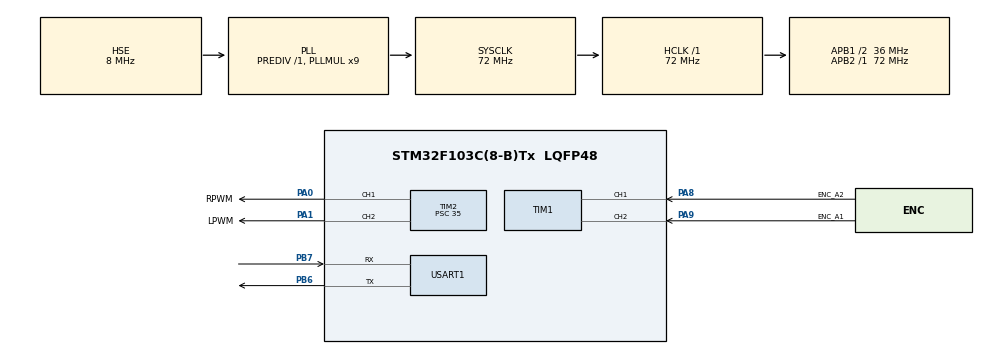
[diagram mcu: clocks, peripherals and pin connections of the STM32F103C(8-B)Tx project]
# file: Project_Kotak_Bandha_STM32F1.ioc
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Mcu.Family=STM32F1
Mcu.Name=STM32F103C(8-B)Tx
Mcu.Package=LQFP48
NVIC.PriorityGroup=NVIC_PRIORITYGROUP_4
PA0-WKUP.GPIO_Label=RPWM
PA0-WKUP.Signal=S_TIM2_CH1_ETR
PA1.GPIO_Label=LPWM
PA1.Signal=S_TIM2_CH2
PA13.Mode=Serial_Wire
PA13.Signal=SYS_JTMS-SWDIO
PA14.Mode=Serial_Wire
PA14.Signal=SYS_JTCK-SWCLK
PA8.GPIO_Label=ENC_A2
PA8.Signal=S_TIM1_CH1
PA9.GPIO_Label=ENC_A1
PA9.Signal=S_TIM1_CH2
PB6.Mode=Asynchronous
PB6.Signal=USART1_TX
PB7.Mode=Asynchronous
PB7.Signal=USART1_RX
PD0-OSC_IN.Mode=HSE-External-Oscillator
PD0-OSC_IN.Signal=RCC_OSC_IN
PD1-OSC_OUT.Mode=HSE-External-Oscillator
PD1-OSC_OUT.Signal=RCC_OSC_OUT
ProjectManager.HeapSize=0x200
ProjectManager.StackSize=0x400
ProjectManager.TargetToolchain=STM32CubeIDE
RCC.AHBFreq_Value=72000000
RCC.APB1CLKDivider=RCC_HCLK_DIV2
RCC.APB1Freq_Value=36000000
RCC.APB1TimFreq_Value=72000000
RCC.APB2Freq_Value=72000000
RCC.APB2TimFreq_Value=72000000
RCC.HCLKFreq_Value=72000000
RCC.PLLMUL=RCC_PLL_MUL9
RCC.PLLSourceVirtual=RCC_PLLSOURCE_HSE
RCC.SYSCLKFreq_VALUE=72000000
RCC.SYSCLKSource=RCC_SYSCLKSOURCE_PLLCLK
RCC.USBFreq_Value=72000000
SH.S_TIM1_CH1.0=TIM1_CH1,Encoder_Interface
SH.S_TIM1_CH2.0=TIM1_CH2,Encoder_Interface
SH.S_TIM2_CH1_ETR.0=TIM2_CH1,PWM Generation1 CH1
SH.S_TIM2_CH2.0=TIM2_CH2,PWM Generation2 CH2
TIM1.EncoderMode=TIM_ENCODERMODE_TI12
TIM2.Channel-PWM\ Generation1\ CH1=TIM_CHANNEL_1
TIM2.Channel-PWM\ Generation2\ CH2=TIM_CHANNEL_2
TIM2.Period=99
TIM2.Prescaler=35
USART1.VirtualMode=VM_ASYNC
board=custom

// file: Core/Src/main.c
/* USER CODE BEGIN Header */
/**
  ******************************************************************************
  * @file           : main.c
  * @brief          : Main program body
  ******************************************************************************
  * @attention
  *
  * Copyright (c) 2026 STMicroelectronics.
  * All rights reserved.
  *
  * This software is licensed under terms that can be found in the LICENSE file
  * in the root directory of this software component.
  * If no LICENSE file comes with this software, it is provided AS-IS.
  *
  ******************************************************************************
  */
/* USER CODE END Header */
#include "main.h"
#include "encoder.h"
#include "motor.h"
#include "pid_control.h"

TIM_HandleTypeDef htim1;
TIM_HandleTypeDef htim2;

UART_HandleTypeDef huart1;

/* USER CODE BEGIN PV */
int16_t encoder_value;
uint16_t duty_cycle = 0;
uint16_t ARR = 99;
/* USER CODE END PV */

void SystemClock_Config(void);
static void MX_GPIO_Init(void);
static void MX_TIM1_Init(void);
static void MX_TIM2_Init(void);
static void MX_USART1_UART_Init(void);

int main(void)
{

  /* MCU Configuration--------------------------------------------------------*/

  /* Reset of all peripherals, Initializes the Flash interface and the Systick. */
  HAL_Init();

  /* Configure the system clock */
  SystemClock_Config();

  /* Initialize all configured peripherals */
  MX_GPIO_Init();
  MX_TIM1_Init();
  MX_TIM2_Init();
  MX_USART1_UART_Init();
  /* USER CODE BEGIN 2 */
  Encoder_Init();
  Motor_Init();
  /* USER CODE END 2 */

  /* Infinite loop */
  /* USER CODE BEGIN WHILE */
  while (1)
  {
	  Encoder_Update();
	  int32_t position = Encoder_GetPosition();
	  HAL_Delay(1);

	  Motor_SetSignedPWM(10);
	  HAL_Delay(100);
	  Motor_Stop();
	  HAL_Delay(1000);
    /* USER CODE END WHILE */

  }
}

void SystemClock_Config(void)
{
  RCC_OscInitTypeDef RCC_OscInitStruct = {0};
  RCC_ClkInitTypeDef RCC_ClkInitStruct = {0};

  /** Initializes the RCC Oscillators according to the specified parameters
  * in the RCC_OscInitTypeDef structure.
  */
  RCC_OscInitStruct.OscillatorType = RCC_OSCILLATORTYPE_HSE;
  RCC_OscInitStruct.HSEState = RCC_HSE_ON;
  RCC_OscInitStruct.HSEPredivValue = RCC_HSE_PREDIV_DIV1;
  RCC_OscInitStruct.HSIState = RCC_HSI_ON;
  RCC_OscInitStruct.PLL.PLLState = RCC_PLL_ON;
  RCC_OscInitStruct.PLL.PLLSource = RCC_PLLSOURCE_HSE;
  RCC_OscInitStruct.PLL.PLLMUL = RCC_PLL_MUL9;
  if (HAL_RCC_OscConfig(&RCC_OscInitStruct) != HAL_OK)
  {
    Error_Handler();
  }

  /** Initializes the CPU, AHB and APB buses clocks
  */
  RCC_ClkInitStruct.ClockType = RCC_CLOCKTYPE_HCLK|RCC_CLOCKTYPE_SYSCLK
                              |RCC_CLOCKTYPE_PCLK1|RCC_CLOCKTYPE_PCLK2;
  RCC_ClkInitStruct.SYSCLKSource = RCC_SYSCLKSOURCE_PLLCLK;
  RCC_ClkInitStruct.AHBCLKDivider = RCC_SYSCLK_DIV1;
  RCC_ClkInitStruct.APB1CLKDivider = RCC_HCLK_DIV2;
  RCC_ClkInitStruct.APB2CLKDivider = RCC_HCLK_DIV1;

  if (HAL_RCC_ClockConfig(&RCC_ClkInitStruct, FLASH_LATENCY_2) != HAL_OK)
  {
    Error_Handler();
  }
}

static void MX_TIM1_Init(void)
{

  TIM_Encoder_InitTypeDef sConfig = {0};
  TIM_MasterConfigTypeDef sMasterConfig = {0};

  htim1.Instance = TIM1;
  htim1.Init.Prescaler = 0;
  htim1.Init.CounterMode = TIM_COUNTERMODE_UP;
  htim1.Init.Period = 65535;
  htim1.Init.ClockDivision = TIM_CLOCKDIVISION_DIV1;
  htim1.Init.RepetitionCounter = 0;
  htim1.Init.AutoReloadPreload = TIM_AUTORELOAD_PRELOAD_DISABLE;
  sConfig.EncoderMode = TIM_ENCODERMODE_TI12;
  sConfig.IC1Polarity = TIM_ICPOLARITY_RISING;
  sConfig.IC1Selection = TIM_ICSELECTION_DIRECTTI;
  sConfig.IC1Prescaler = TIM_ICPSC_DIV1;
  sConfig.IC1Filter = 0;
  sConfig.IC2Polarity = TIM_ICPOLARITY_RISING;
  sConfig.IC2Selection = TIM_ICSELECTION_DIRECTTI;
  sConfig.IC2Prescaler = TIM_ICPSC_DIV1;
  sConfig.IC2Filter = 0;
  if (HAL_TIM_Encoder_Init(&htim1, &sConfig) != HAL_OK)
  {
    Error_Handler();
  }
  sMasterConfig.MasterOutputTrigger = TIM_TRGO_RESET;
  sMasterConfig.MasterSlaveMode = TIM_MASTERSLAVEMODE_DISABLE;
  if (HAL_TIMEx_MasterConfigSynchronization(&htim1, &sMasterConfig) != HAL_OK)
  {
    Error_Handler();
  }

}

static void MX_TIM2_Init(void)
{

  TIM_MasterConfigTypeDef sMasterConfig = {0};
  TIM_OC_InitTypeDef sConfigOC = {0};

  htim2.Instance = TIM2;
  htim2.Init.Prescaler = 35;
  htim2.Init.CounterMode = TIM_COUNTERMODE_UP;
  htim2.Init.Period = 99;
  htim2.Init.ClockDivision = TIM_CLOCKDIVISION_DIV1;
  htim2.Init.AutoReloadPreload = TIM_AUTORELOAD_PRELOAD_DISABLE;
  if (HAL_TIM_PWM_Init(&htim2) != HAL_OK)
  {
    Error_Handler();
  }
  sMasterConfig.MasterOutputTrigger = TIM_TRGO_RESET;
  sMasterConfig.MasterSlaveMode = TIM_MASTERSLAVEMODE_DISABLE;
  if (HAL_TIMEx_MasterConfigSynchronization(&htim2, &sMasterConfig) != HAL_OK)
  {
    Error_Handler();
  }
  sConfigOC.OCMode = TIM_OCMODE_PWM1;
  sConfigOC.Pulse = 0;
  sConfigOC.OCPolarity = TIM_OCPOLARITY_HIGH;
  sConfigOC.OCFastMode = TIM_OCFAST_DISABLE;
  if (HAL_TIM_PWM_ConfigChannel(&htim2, &sConfigOC, TIM_CHANNEL_1) != HAL_OK)
  {
    Error_Handler();
  }
  if (HAL_TIM_PWM_ConfigChannel(&htim2, &sConfigOC, TIM_CHANNEL_2) != HAL_OK)
  {
    Error_Handler();
  }
  HAL_TIM_MspPostInit(&htim2);

}

static void MX_USART1_UART_Init(void)
{

  huart1.Instance = USART1;
  huart1.Init.BaudRate = 115200;
  huart1.Init.WordLength = UART_WORDLENGTH_8B;
  huart1.Init.StopBits = UART_STOPBITS_1;
  huart1.Init.Parity = UART_PARITY_NONE;
  huart1.Init.Mode = UART_MODE_TX_RX;
  huart1.Init.HwFlowCtl = UART_HWCONTROL_NONE;
  huart1.Init.OverSampling = UART_OVERSAMPLING_16;
  if (HAL_UART_Init(&huart1) != HAL_OK)
  {
    Error_Handler();
  }

}

static void MX_GPIO_Init(void)
{

  /* GPIO Ports Clock Enable */
  __HAL_RCC_GPIOD_CLK_ENABLE();
  __HAL_RCC_GPIOA_CLK_ENABLE();
  __HAL_RCC_GPIOB_CLK_ENABLE();

}

void Error_Handler(void)
{
  __disable_irq();
  while (1)
  {
  }
}
